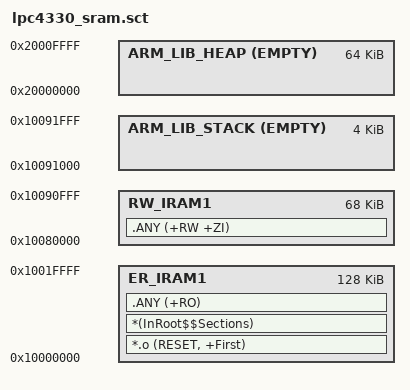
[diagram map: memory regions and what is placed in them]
;*****************************************************************
;* LPC4330 linker scatter file (running code from internal SRAM) *
;*****************************************************************

LR_IRAM1 0x10000000 0x20000
{
   ER_IRAM1 0x10000000 0x20000
   {
      *.o (RESET, +First)
      *(InRoot$$Sections)
      .ANY (+RO)
   }
   
   RW_IRAM1 0x10080000 0x11000
   { 
      .ANY (+RW +ZI)
   }
   
   ARM_LIB_STACK 0x10092000 EMPTY -0x1000
   {
   }
   
   ARM_LIB_HEAP 0x20000000 EMPTY 0x10000
   {
   }
}
